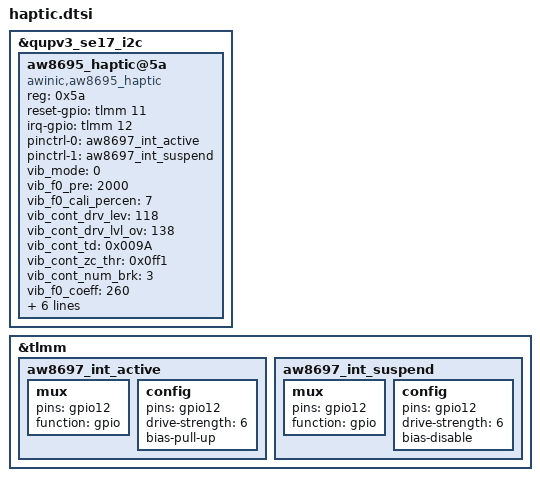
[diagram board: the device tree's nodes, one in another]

/* AWINIC AW8695 Haptic */
&qupv3_se17_i2c {
    status = "ok";
        aw8695_haptic@5a {
        compatible = "awinic,aw8695_haptic";
        reg = <0x5a>;
        reset-gpio = <&tlmm 11 0>;
        irq-gpio = <&tlmm 12 0>;

        pinctrl-names = "aw8697_int_active", "aw8697_int_suspend";
        pinctrl-0 = <&aw8697_int_active>;
        pinctrl-1 = <&aw8697_int_suspend>;

        vib_mode = < 0 >;   /*mode:   RAM mode->0; CONT mode -> 1*/
        vib_f0_pre = < 2000 >;
        vib_f0_cali_percen = < 7 >;
        vib_cont_drv_lev = < 118 >;
        vib_cont_drv_lvl_ov = < 138 >;
        vib_cont_td = < 0x009A >;
        vib_cont_zc_thr = < 0x0ff1 >;  /*hq 0x08F8 */
        vib_cont_num_brk = < 3 >;
        vib_f0_coeff = < 260 >; /*Don't modify it    2.604167*/
        vib_f0_trace_parameter = < 0x05 0x03 0x02 0x0f >;
        vib_bemf_config = < 0x10 0x08 0x03 0xf8 >;
        vib_sw_brake = < 0x2c >;
        vib_tset = < 0x12 >;
        vib_r_spare = < 0x68 >;
        vib_bstdbg = < 0x30 0xeb 0xd4 0 0 0 >;
        status = "okay";
    };
};
&tlmm {
    aw8697_int_active: aw8697_int_active {
        mux {
            pins = "gpio12";
            function = "gpio";
        };

        config {
            pins = "gpio12";
            drive-strength = <6>;
            bias-pull-up;
        };

    };

    aw8697_int_suspend: aw8697_int_suspend {
        mux {
            pins = "gpio12";
            function = "gpio";
        };

        config {
            pins = "gpio12";
            drive-strength = <6>;
            bias-disable;
        };

    };
};
/* AWINIC AW8695: Haptic End */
